# SAM4S8A/SAM4S16A register map
File version: 0
Registers are 32-bit, read-write, reset 0x0 unless marked. A register's access mark holds for its fields unless they carry their own. Offsets are from the block's base; [hi:lo] are bit positions; {n}, {i} and the like mark numbered series.

## ACC — Analog Comparator Controller
Base 0x40040000; register names take the prefix ACC_
0x00 CR wo reset not defined — Control Register
  [0] SWRST — SoftWare ReSeT
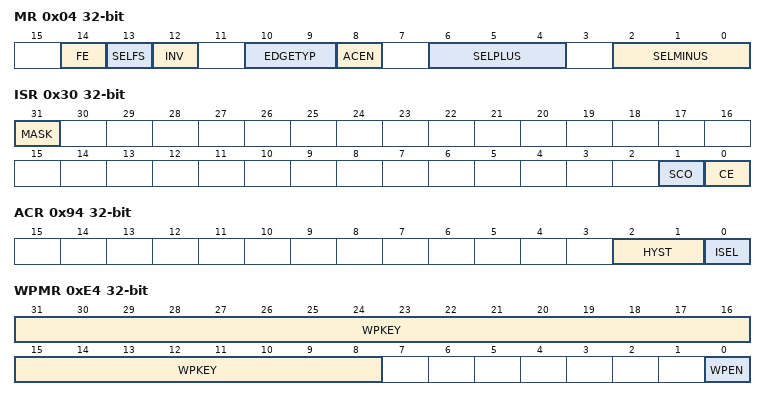
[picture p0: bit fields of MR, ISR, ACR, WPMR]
0x04 MR — Mode Register
  [14] FE — Fault Enable
    0=DIS (the FAULT output is tied to 0.); 1=EN (the FAULT output is driven by the signal defined by SELFS.)
  [13] SELFS — SELection of Fault Source
    0=CF (the CF flag is used to drive the FAULT output.); 1=OUTPUT (the output of the Analog Comparator flag is used to drive the FAULT output.)
  [12] INV — INVert comparator output
    0=DIS (Analog Comparator output is directly processed.); 1=EN (Analog Comparator output is inverted prior to being processed.)
  [10:9] EDGETYP — EDGE TYPe
    0=RISING (only rising edge of comparator output); 1=FALLING (falling edge of comparator output); 2=ANY (any edge of comparator output)
  [8] ACEN — Analog Comparator ENable
    0=DIS (Analog Comparator Disabled.); 1=EN (Analog Comparator Enabled.)
  [6:4] SELPLUS — SELection for PLUS comparator input
    {v}=AD{v} (Select AD{v}) (v=0..7)
  [2:0] SELMINUS — SELection for MINUS comparator input
    0=TS (SelectTS); 1=ADVREF (Select ADVREF); 2=DAC0 (Select DAC0); 3=DAC1 (Select DAC1); {v}=AD{v-4} (Select AD{v-4}) (v=4..7)
0x24 IER wo reset not defined — Interrupt Enable Register
  [0] CE — Comparison Edge
0x28 IDR wo reset not defined — Interrupt Disable Register
  [0] CE — Comparison Edge
0x2C IMR ro — Interrupt Mask Register
  [0] CE — Comparison Edge
0x30 ISR ro — Interrupt Status Register
  [31] MASK
  [1] SCO — Synchronized Comparator Output
  [0] CE — Comparison Edge
0x94 ACR — Analog Control Register
  [2:1] HYST — HYSTeresis selection
  [0] ISEL — Current SELection
    0=LOPW (low power option.); 1=HISP (high speed option.)
0xE4 WPMR — Write Protect Mode Register
  [31:8] WPKEY — Write Protect KEY
  [0] WPEN — Write Protect Enable
0xE8 WPSR ro — Write Protect Status Register
  [0] WPROTERR — Write PROTection ERRor

## CRCCU — Cyclic Redundancy Check Calculation Unit
Base 0x40044000; register names take the prefix CRCCU_
0x00 DSCR — CRCCU Descriptor Base Register
  [31:9] DSCR — Descriptor Base Address
0x08 DMA_EN wo — CRCCU DMA Enable Register
  [0] DMAEN — DMA Enable Register
0x0C DMA_DIS wo — CRCCU DMA Disable Register
  [0] DMADIS — DMA Disable Register
0x10 DMA_SR ro — CRCCU DMA Status Register
  [0] DMASR — DMA Status Register
0x14 DMA_IER wo — CRCCU DMA Interrupt Enable Register
  [0] DMAIER — Interrupt Enable register
0x18 DMA_IDR wo — CRCCU DMA Interrupt Disable Register
  [0] DMAIDR — Interrupt Disable register
0x1C DMA_IMR ro — CRCCU DMA Interrupt Mask Register
  [0] DMAIMR — Interrupt Mask Register
0x20 DMA_ISR ro — CRCCU DMA Interrupt Status Register
  [0] DMAISR — Interrupt Status register
0x34 CR wo — CRCCU Control Register
  [0] RESET — CRC Computation Reset
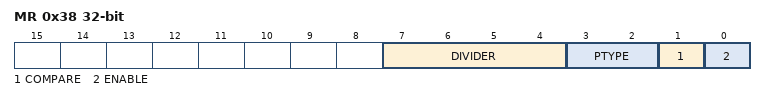
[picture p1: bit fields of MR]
0x38 MR — CRCCU Mode Register
  [7:4] DIVIDER — Request Divider
  [3:2] PTYPE — Primitive Polynomial
    0=CCIT8023 (Polynom 0x04C11DB7); 1=CASTAGNOLI (Polynom 0x1EDC6F41); 2=CCIT16 (Polynom 0x1021)
  [1] COMPARE — CRC Compare
  [0] ENABLE — CRC Enable
0x3C SR ro reset 0xFFFFFFFF — CRCCU Status Register
  [31:0] CRC — Cyclic Redundancy Check Value
0x40 IER wo — CRCCU Interrupt Enable Register
  [0] ERRIER — CRC Error Interrupt Enable
0x44 IDR wo — CRCCU Interrupt Disable Register
  [0] ERRIDR — CRC Error Interrupt Disable
0x48 IMR ro — CRCCU Interrupt Mask Register
  [0] ERRIMR — CRC Error Interrupt Mask
0x4C ISR ro — CRCCU Interrupt Status Register
  [0] ERRISR — CRC Error Interrupt Status

## MATRIX — AHB Bus Matrix
Base 0x400E0200
{0x0+4i} MATRIX_MCFG{i} (i=0..3) reset not defined — Master Configuration Register
  [2:0] ULBT — Undefined Length Burst Type
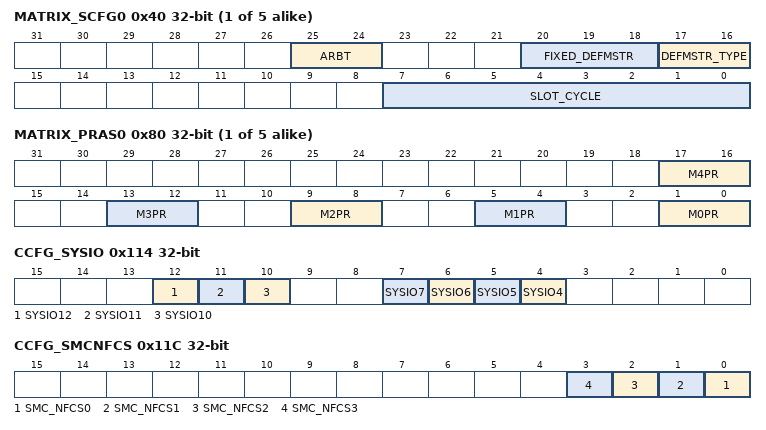
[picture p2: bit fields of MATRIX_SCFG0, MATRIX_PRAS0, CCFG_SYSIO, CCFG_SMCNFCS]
{0x40+4i} MATRIX_SCFG{i} (i=0..4) reset not defined — Slave Configuration Register
  [25:24] ARBT — Arbitration Type
  [20:18] FIXED_DEFMSTR — Fixed Default Master
  [17:16] DEFMSTR_TYPE — Default Master Type
  [7:0] SLOT_CYCLE — Maximum Number of Allowed Cycles for a Burst
{0x80+8i} MATRIX_PRAS{i} (i=0..4) — Priority Register A for Slave {i}
  [4n+1:4n] M{n}PR (n=0..4) — Master {n} Priority
0x114 CCFG_SYSIO — System I/O Configuration register
  [12] SYSIO12 — PB12 or ERASE Assignment
  [11] SYSIO11 — PB11 or DDP Assignment
  [10] SYSIO10 — PB10 or DDM Assignment
  [7] SYSIO7 — PB7 or TCK/SWCLK Assignment
  [6] SYSIO6 — PB6 or TMS/SWDIO Assignment
  [5] SYSIO5 — PB5 or TDO/TRACESWO Assignment
  [4] SYSIO4 — PB4 or TDI Assignment
0x11C CCFG_SMCNFCS — SMC Chip Select NAND Flash Assignment Register
  [n] SMC_NFCS{n} (n=0..3) — SMC NAND Flash Chip Select {n} Assignment
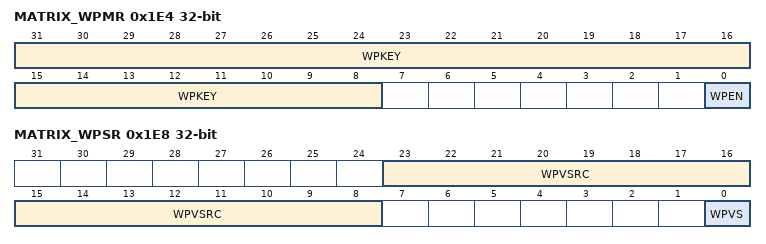
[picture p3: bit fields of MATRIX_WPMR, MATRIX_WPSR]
0x1E4 MATRIX_WPMR — Write Protect Mode Register
  [31:8] WPKEY — Write Protect KEY (Write-only)
  [0] WPEN — Write Protect ENable
0x1E8 MATRIX_WPSR ro — Write Protect Status Register
  [23:8] WPVSRC — Write Protect Violation Source
  [0] WPVS — Write Protect Violation Status
